VERSION "created by canmatrix"

NS_ :

BS_:

BU_: ACU VCU

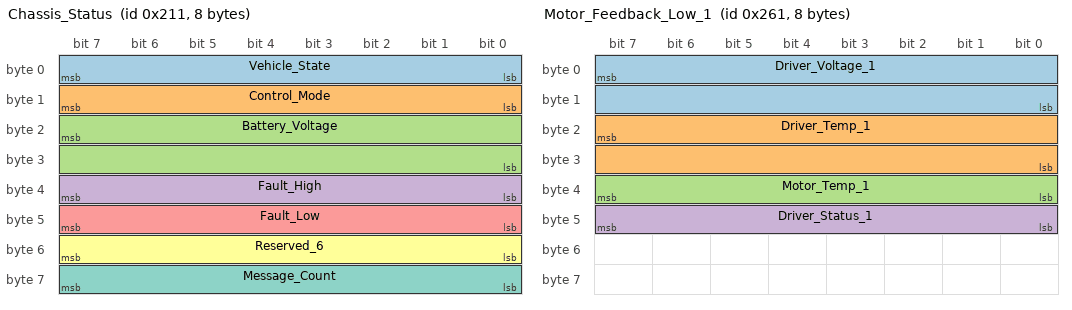
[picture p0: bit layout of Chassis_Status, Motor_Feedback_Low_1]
BO_ 529 Chassis_Status: 8 VCU
 SG_ Vehicle_State : 7|8@0+ (1,0) [0|255] ""  ACU
 SG_ Control_Mode : 15|8@0+ (1,0) [0|255] ""  ACU
 SG_ Battery_Voltage : 23|16@0+ (0.1,0) [0|65535] "V"  ACU
 SG_ Fault_High : 39|8@0+ (1,0) [0|255] ""  ACU
 SG_ Fault_Low : 47|8@0+ (1,0) [0|255] ""  ACU
 SG_ Reserved_6 : 55|8@0+ (1,0) [0|255] ""  ACU
 SG_ Message_Count : 63|8@0+ (1,0) [0|255] ""  ACU

BO_ 1057 Control_Mode_Set: 8 ACU
 SG_ Mode_Set : 7|8@0+ (1,0) [0|2] ""  VCU

BO_ 1089 Error_Clear_Command: 8 ACU
 SG_ Clear_Code : 7|8@0+ (1,0) [0|255] ""  VCU

BO_ 273 Motion_Command: 8 ACU
 SG_ Target_Speed : 7|16@0- (0.001,0) [-4800|4800] "m/s"  VCU
 SG_ Target_Steer_Angle : 55|16@0- (0.001,0) [-400|400] "rad"  VCU

BO_ 545 Motion_Feedback: 8 VCU
 SG_ Linear_Speed : 7|16@0- (0.001,0) [-32768|32767] "m/s"  ACU
 SG_ Steering_Angle : 55|16@0- (0.001,0) [-32768|32767] "rad"  ACU

BO_ 593 Motor_Feedback_High_1: 8 VCU
 SG_ Motor1_Speed : 7|16@0- (1,0) [-32768|32767] "RPM"  ACU
 SG_ Motor1_Current : 23|16@0- (0.1,0) [-32768|32767] "A"  ACU

BO_ 594 Motor_Feedback_High_2: 8 VCU
 SG_ Motor2_Speed : 7|16@0- (1,0) [-32768|32767] "RPM"  ACU
 SG_ Motor2_Current : 23|16@0- (0.1,0) [-32768|32767] "A"  ACU

BO_ 595 Motor_Feedback_High_3: 8 VCU
 SG_ Motor3_Speed : 7|16@0- (1,0) [-32768|32767] "RPM"  ACU
 SG_ Motor3_Current : 23|16@0- (0.1,0) [-32768|32767] "A"  ACU

BO_ 609 Motor_Feedback_Low_1: 8 VCU
 SG_ Driver_Voltage_1 : 7|16@0+ (0.1,0) [0|65535] "V"  ACU
 SG_ Driver_Temp_1 : 23|16@0- (1,0) [-32768|32767] "degC"  ACU
 SG_ Motor_Temp_1 : 39|8@0- (1,0) [-128|127] "degC"  ACU
 SG_ Driver_Status_1 : 47|8@0+ (1,0) [0|255] ""  ACU

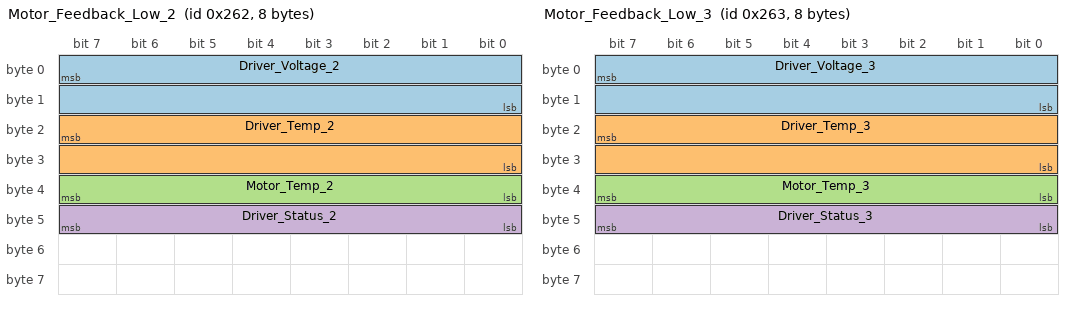
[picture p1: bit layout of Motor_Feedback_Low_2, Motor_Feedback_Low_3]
BO_ 610 Motor_Feedback_Low_2: 8 VCU
 SG_ Driver_Voltage_2 : 7|16@0+ (0.1,0) [0|65535] "V"  ACU
 SG_ Driver_Temp_2 : 23|16@0- (1,0) [-32768|32767] "degC"  ACU
 SG_ Motor_Temp_2 : 39|8@0- (1,0) [-128|127] "degC"  ACU
 SG_ Driver_Status_2 : 47|8@0+ (1,0) [0|255] ""  ACU

BO_ 611 Motor_Feedback_Low_3: 8 VCU
 SG_ Driver_Voltage_3 : 7|16@0+ (0.1,0) [0|65535] "V"  ACU
 SG_ Driver_Temp_3 : 23|16@0- (1,0) [-32768|32767] "degC"  ACU
 SG_ Motor_Temp_3 : 39|8@0- (1,0) [-128|127] "degC"  ACU
 SG_ Driver_Status_3 : 47|8@0+ (1,0) [0|255] ""  ACU

VAL_ 529 Vehicle_State 2 "SystemFault" 1 "EmergencyStop" 0 "Normal" ;
VAL_ 529 Control_Mode 2 "Remote" 1 "CANcontrol" 0 "Standby" ;
VAL_ 1057 Mode_Set 2 "Tostandby" 1 "CanControl" 0 "Standby" ;
VAL_ 1089 Clear_Code 6 "ClearLbFault" 5 "ClearRbFault" 4 "ClearTurnFault" 255 "ClearAll" ;
